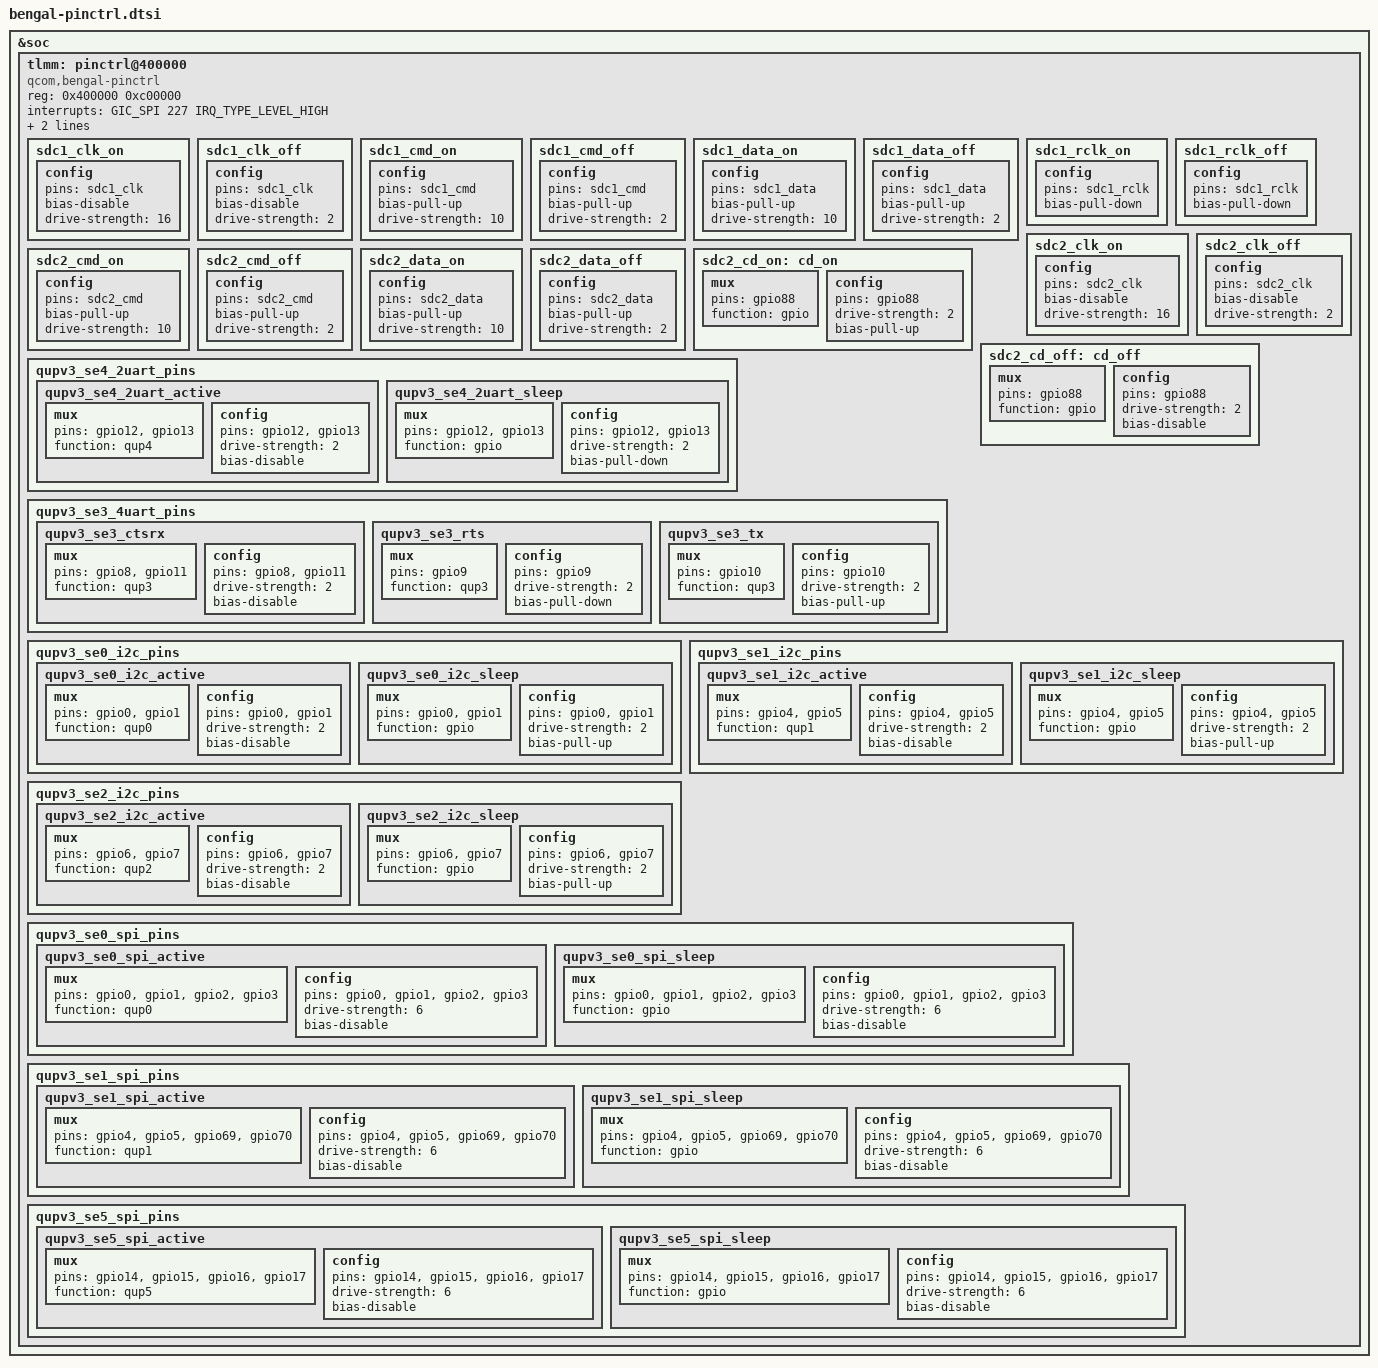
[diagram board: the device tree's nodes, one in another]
&soc {
	tlmm: pinctrl@400000 {
		compatible = "qcom,bengal-pinctrl";
		reg = <0x400000 0xc00000>;
		interrupts = <GIC_SPI 227 IRQ_TYPE_LEVEL_HIGH>;
		gpio-controller;
		#gpio-cells = <2>;
		interrupt-controller;
		#interrupt-cells = <2>;

		/* SDC pin type */
		sdc1_clk_on: sdc1_clk_on {
			config {
				pins = "sdc1_clk";
				bias-disable;		/* NO pull */
				drive-strength = <16>;	/* 16 MA */
			};
		};

		sdc1_clk_off: sdc1_clk_off {
			config {
				pins = "sdc1_clk";
				bias-disable;		/* NO pull */
				drive-strength = <2>;	/* 2 MA */
			};
		};

		sdc1_cmd_on: sdc1_cmd_on {
			config {
				pins = "sdc1_cmd";
				bias-pull-up;		/* pull up */
				drive-strength = <10>;	/* 10 MA */
			};
		};

		sdc1_cmd_off: sdc1_cmd_off {
			config {
				pins = "sdc1_cmd";
				bias-pull-up;		/* pull up */
				drive-strength = <2>;	/* 2 MA */
			};
		};

		sdc1_data_on: sdc1_data_on {
			config {
				pins = "sdc1_data";
				bias-pull-up;		/* pull up */
				drive-strength = <10>;	/* 10 MA */
			};
		};

		sdc1_data_off: sdc1_data_off {
			config {
				pins = "sdc1_data";
				bias-pull-up;		/* pull up */
				drive-strength = <2>;	/* 2 MA */
			};
		};

		sdc1_rclk_on: sdc1_rclk_on {
			config {
				pins = "sdc1_rclk";
				bias-pull-down; /* pull down */
			};
		};

		sdc1_rclk_off: sdc1_rclk_off {
			config {
				pins = "sdc1_rclk";
				bias-pull-down; /* pull down */
			};
		};

		sdc2_clk_on: sdc2_clk_on {
			config {
				pins = "sdc2_clk";
				bias-disable;		/* NO pull */
				drive-strength = <16>;	/* 16 MA */
			};
		};

		sdc2_clk_off: sdc2_clk_off {
			config {
				pins = "sdc2_clk";
				bias-disable;		/* NO pull */
				drive-strength = <2>;	/* 2 MA */
			};
		};

		sdc2_cmd_on: sdc2_cmd_on {
			config {
				pins = "sdc2_cmd";
				bias-pull-up;		/* pull up */
				drive-strength = <10>;	/* 10 MA */
			};
		};

		sdc2_cmd_off: sdc2_cmd_off {
			config {
				pins = "sdc2_cmd";
				bias-pull-up;		/* pull up */
				drive-strength = <2>;	/* 2 MA */
			};
		};

		sdc2_data_on: sdc2_data_on {
			config {
				pins = "sdc2_data";
				bias-pull-up;		/* pull up */
				drive-strength = <10>;	/* 10 MA */
			};
		};

		sdc2_data_off: sdc2_data_off {
			config {
				pins = "sdc2_data";
				bias-pull-up;		/* pull up */
				drive-strength = <2>;	/* 2 MA */
			};
		};

		sdc2_cd_on: cd_on {
			mux {
				pins = "gpio88";
				function = "gpio";
			};

			config {
				pins = "gpio88";
				drive-strength = <2>;
				bias-pull-up;
			};
		};

		sdc2_cd_off: cd_off {
			mux {
				pins = "gpio88";
				function = "gpio";
			};

			config {
				pins = "gpio88";
				drive-strength = <2>;
				bias-disable;
			};
		};

		qupv3_se4_2uart_pins: qupv3_se4_2uart_pins {
			qupv3_se4_2uart_active: qupv3_se4_2uart_active {
				mux {
					pins = "gpio12", "gpio13";
					function = "qup4";
				};

				config {
					pins = "gpio12", "gpio13";
					drive-strength = <2>;
					bias-disable;
				};
			};

			qupv3_se4_2uart_sleep: qupv3_se4_2uart_sleep {
				mux {
					pins = "gpio12", "gpio13";
					function = "gpio";
				};

				config {
					pins = "gpio12", "gpio13";
					drive-strength = <2>;
					bias-pull-down;
				};
			};
		};

		qupv3_se3_4uart_pins: qupv3_se3_4uart_pins {
			qupv3_se3_ctsrx: qupv3_se3_ctsrx {
				mux {
					pins = "gpio8", "gpio11";
					function = "qup3";
				};

				config {
					pins = "gpio8", "gpio11";
					drive-strength = <2>;
					bias-disable;
				};
			};

			qupv3_se3_rts: qupv3_se3_rts {
				mux {
					pins = "gpio9";
					function = "qup3";
				};

				config {
					pins = "gpio9";
					drive-strength = <2>;
					bias-pull-down;
				};
			};

			qupv3_se3_tx: qupv3_se3_tx {
				mux {
					pins = "gpio10";
					function = "qup3";
				};

				config {
					pins = "gpio10";
					drive-strength = <2>;
					bias-pull-up;
				};
			};
		};

		qupv3_se0_i2c_pins: qupv3_se0_i2c_pins {
			qupv3_se0_i2c_active: qupv3_se0_i2c_active {
				mux {
					pins = "gpio0", "gpio1";
					function = "qup0";
				};

				config {
					pins = "gpio0", "gpio1";
					drive-strength = <2>;
					bias-disable;
				};
			};

			qupv3_se0_i2c_sleep: qupv3_se0_i2c_sleep {
				mux {
					pins = "gpio0", "gpio1";
					function = "gpio";
				};

				config {
					pins = "gpio0", "gpio1";
					drive-strength = <2>;
					bias-pull-up;
				};
			};
		};

		qupv3_se1_i2c_pins: qupv3_se1_i2c_pins {
			qupv3_se1_i2c_active: qupv3_se1_i2c_active {
				mux {
					pins = "gpio4", "gpio5";
					function = "qup1";
				};

				config {
					pins = "gpio4", "gpio5";
					drive-strength = <2>;
					bias-disable;
				};
			};

			qupv3_se1_i2c_sleep: qupv3_se1_i2c_sleep {
				mux {
					pins = "gpio4", "gpio5";
					function = "gpio";
				};

				config {
					pins = "gpio4", "gpio5";
					drive-strength = <2>;
					bias-pull-up;
				};
			};
		};

		qupv3_se2_i2c_pins: qupv3_se2_i2c_pins {
			qupv3_se2_i2c_active: qupv3_se2_i2c_active {
				mux {
					pins = "gpio6", "gpio7";
					function = "qup2";
				};

				config {
					pins = "gpio6", "gpio7";
					drive-strength = <2>;
					bias-disable;
				};
			};

			qupv3_se2_i2c_sleep: qupv3_se2_i2c_sleep {
				mux {
					pins = "gpio6", "gpio7";
					function = "gpio";
				};

				config {
					pins = "gpio6", "gpio7";
					drive-strength = <2>;
					bias-pull-up;
				};
			};
		};

		qupv3_se0_spi_pins: qupv3_se0_spi_pins {
			qupv3_se0_spi_active: qupv3_se0_spi_active {
				mux {
					pins = "gpio0", "gpio1",
							"gpio2", "gpio3";
					function = "qup0";
				};

				config {
					pins = "gpio0", "gpio1",
							"gpio2", "gpio3";
					drive-strength = <6>;
					bias-disable;
				};
			};

			qupv3_se0_spi_sleep: qupv3_se0_spi_sleep {
				mux {
					pins = "gpio0", "gpio1",
							"gpio2", "gpio3";
					function = "gpio";
				};

				config {
					pins = "gpio0", "gpio1",
							"gpio2", "gpio3";
					drive-strength = <6>;
					bias-disable;
				};
			};
		};

		qupv3_se1_spi_pins: qupv3_se1_spi_pins {
			qupv3_se1_spi_active: qupv3_se1_spi_active {
				mux {
					pins = "gpio4", "gpio5",
							"gpio69", "gpio70";
					function = "qup1";
				};

				config {
					pins = "gpio4", "gpio5",
							"gpio69", "gpio70";
					drive-strength = <6>;
					bias-disable;
				};
			};

			qupv3_se1_spi_sleep: qupv3_se1_spi_sleep {
				mux {
					pins = "gpio4", "gpio5",
							"gpio69", "gpio70";
					function = "gpio";
				};

				config {
					pins = "gpio4", "gpio5",
							"gpio69", "gpio70";
					drive-strength = <6>;
					bias-disable;
				};
			};
		};

		qupv3_se5_spi_pins: qupv3_se5_spi_pins {
			qupv3_se5_spi_active: qupv3_se5_spi_active {
				mux {
					pins = "gpio14", "gpio15",
							"gpio16", "gpio17";
					function = "qup5";
				};

				config {
					pins = "gpio14", "gpio15",
							"gpio16", "gpio17";
					drive-strength = <6>;
					bias-disable;
				};
			};

			qupv3_se5_spi_sleep: qupv3_se5_spi_sleep {
				mux {
					pins = "gpio14", "gpio15",
							"gpio16", "gpio17";
					function = "gpio";
				};

				config {
					pins = "gpio14", "gpio15",
							"gpio16", "gpio17";
					drive-strength = <6>;
					bias-disable;
				};
			};
		};
	};
};
